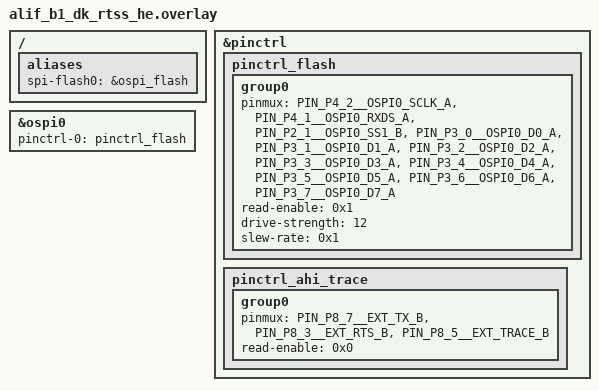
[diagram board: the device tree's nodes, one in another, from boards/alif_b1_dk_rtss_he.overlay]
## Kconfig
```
# Copyright (C) Alif Semiconductor - All Rights Reserved.
# Use, distribution and modification of this code is permitted under the
# terms stated in the Alif Semiconductor Software License Agreement
#
# You should have received a copy of the Alif Semiconductor Software
# License Agreement with this file. If not, please write to:
# contact@alifsemi.com, or visit: https://alifsemi.com/license

mainmenu "Alif OSPI flash sample"

config ALIF_OSPI_FLASH_BOOT_XIP_IMAGE
	bool "Boot image from OSPI XIP"
	depends on ALIF_OSPI_FLASH_XIP
	help
	  Boot or jump to an image stored in OSPI flash XIP address space.
	  This option is only for demonstration purposes.

source "Kconfig.zephyr"
```

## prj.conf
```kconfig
# Copyright (C) 2026 Alif Semiconductor.
# SPDX-License-Identifier: Apache-2.0

CONFIG_STDOUT_CONSOLE=y
CONFIG_FLASH=y
CONFIG_LOG=y
CONFIG_EVENTS=y
CONFIG_MAIN_STACK_SIZE=8192
CONFIG_FLASH_LOG_LEVEL_DBG=n
CONFIG_LOG_MODE_IMMEDIATE=y

#For Enable XiP
CONFIG_ALIF_OSPI_FLASH_XIP=n

#For Booting image in XiP mode from flash
CONFIG_ALIF_OSPI_FLASH_BOOT_XIP_IMAGE=n
```

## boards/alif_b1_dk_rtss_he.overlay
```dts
/* Copyright (C) 2024 Alif Semiconductor - All Rights Reserved.
 * Use, distribution and modification of this code is permitted under the
 * terms stated in the Alif Semiconductor Software License Agreement
 *
 * You should have received a copy of the Alif Semiconductor Software
 * License Agreement with this file. If not, please write to:
 * contact@alifsemi.com, or visit: https://alifsemi.com/license
 */

/{
	aliases {
		spi-flash0 = &ospi_flash;
	};
};

&pinctrl {
	//Flash connected with "P2_1_OSPI0_SS1_B" CS line
	pinctrl_flash:pinctrl_flash {
		group0 {
			pinmux = <PIN_P4_2__OSPI0_SCLK_A>,
				 <PIN_P4_1__OSPI0_RXDS_A>,
				 <PIN_P2_1__OSPI0_SS1_B>,
				 <PIN_P3_0__OSPI0_D0_A>,
				 <PIN_P3_1__OSPI0_D1_A>,
				 <PIN_P3_2__OSPI0_D2_A>,
				 <PIN_P3_3__OSPI0_D3_A>,
				 <PIN_P3_4__OSPI0_D4_A>,
				 <PIN_P3_5__OSPI0_D5_A>,
				 <PIN_P3_6__OSPI0_D6_A>,
				 <PIN_P3_7__OSPI0_D7_A>;
			read-enable = <0x1>;
			drive-strength = <12>;
			slew-rate = <0x1>;
		};
	};

	//Default AHI Trace pins affects OSPI-Flash pins.
	pinctrl_ahi_trace: pinctrl_ahi_trace {
		group0 {
			pinmux = <PIN_P8_7__EXT_TX_B>,
				 <PIN_P8_3__EXT_RTS_B>,
				 <PIN_P8_5__EXT_TRACE_B>;
			read-enable = < 0x0 >;
		};
	};
};

&ospi0 {
	pinctrl-0 = <&pinctrl_flash>;
	status = "okay";
};
```

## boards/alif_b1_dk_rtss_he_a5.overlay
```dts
/* Copyright (C) 2025 Alif Semiconductor - All Rights Reserved.
 * Use, distribution and modification of this code is permitted under the
 * terms stated in the Alif Semiconductor Software License Agreement
 *
 * You should have received a copy of the Alif Semiconductor Software
 * License Agreement with this file. If not, please write to:
 * contact@alifsemi.com, or visit: https://alifsemi.com/license
 */

/*
 * OSPI0 Test with Flash
 */
/{
	aliases {
		spi-flash0 = &ospi_flash;
	};
};

&ospi0 {
	pinctrl-0 = <&pinctrl_flash>;
	xip-base-address = <0xB0000000 0x20000000>;
	status = "okay";
};


&pinctrl {
	//A5-B1-DK Flash connected with "P2_1_OSPI0_SS1_B" CS line
	pinctrl_flash:pinctrl_flash {
		group0 {
			pinmux = <PIN_P4_2__OSPI0_SCLK_A>,
				 <PIN_P4_1__OSPI0_RXDS_A>,
				 <PIN_P2_1__OSPI0_SS1_B>,
				 <PIN_P3_0__OSPI0_D0_A>,
				 <PIN_P3_1__OSPI0_D1_A>,
				 <PIN_P3_2__OSPI0_D2_A>,
				 <PIN_P3_3__OSPI0_D3_A>,
				 <PIN_P3_4__OSPI0_D4_A>,
				 <PIN_P3_5__OSPI0_D5_A>,
				 <PIN_P3_6__OSPI0_D6_A>,
				 <PIN_P3_7__OSPI0_D7_A>;
			read_enable = <0x1>;
			drive_strength = <12>;
			slew_rate = <0x1>;
		};
	};

	//Default AHI Trace pins affects connected OSPI-Flash pins.
	pinctrl_ahi_trace: pinctrl_ahi_trace {
		group0 {
			pinmux = <PIN_P8_7__EXT_TX_B>,
				 <PIN_P8_3__EXT_RTS_B>,
				 <PIN_P8_5__EXT_TRACE_B>;
			read_enable = < 0x0 >;
		};
	};
};
```

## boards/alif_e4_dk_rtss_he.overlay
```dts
/* Copyright (C) 2025 Alif Semiconductor - All Rights Reserved.
 * Use, distribution and modification of this code is permitted under the
 * terms stated in the Alif Semiconductor Software License Agreement
 *
 * You should have received a copy of the Alif Semiconductor Software
 * License Agreement with this file. If not, please write to:
 * contact@alifsemi.com, or visit: https: //alifsemi.com/license
 *
 */

/*
 * For OSPI1 Test with Flash
 */

/ {
	aliases {
		spi-flash0 = &ospi_flash;
	};
};

&ospi1 {
	status = "okay";
	pinctrl-0 = <&pinctrl_flash>;
};
```

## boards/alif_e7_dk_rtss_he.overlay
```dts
/*
 * Copyright (c) 2024 Alif Semiconductor.
 * SPDX-License-Identifier: Apache-2.0
 */


/* For OSPI1 Test with Flash
 *
 */
/ {
	aliases {
		spi-flash0 = &ospi1;
	};
};
&ospi1 {
        pinctrl-0 = <&pinctrl_flash>;
	status = "okay";
};
```

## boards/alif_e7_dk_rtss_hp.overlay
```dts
/*
 * Copyright (c) 2024 Alif Semiconductor.
 * SPDX-License-Identifier: Apache-2.0
 */

/ {
	aliases {
		spi-flash0 = &ospi1;
	};
};
&ospi1 {
	status = "okay";
        pinctrl-0 = <&pinctrl_flash>;
};
```

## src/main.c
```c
/*
 * Copyright (c) 2024 Alif Semiconductor
 * SPDX-License-Identifier: Apache-2.0
 */

#include <stdio.h>
#include <string.h>
#include <zephyr/device.h>
#include <zephyr/devicetree.h>
#include <zephyr/drivers/flash.h>
#include <zephyr/kernel.h>

#define SPI_FLASH_TEST_REGION_OFFSET 0x0
#define SPI_FLASH_SECTOR_SIZE        4096
#define BUFF_SIZE                    1024

#ifdef CONFIG_ALIF_OSPI_FLASH_XIP
#define XIP_IMAGE_BASE DT_PROP_BY_IDX(DT_PARENT(DT_ALIAS(spi_flash0)), xip_base_address, 0)

FUNC_NORETURN static void boot_xip_image(void)
{
	uint32_t image_base = XIP_IMAGE_BASE;
	uint32_t initial_sp = *(uint32_t *)image_base;
	uint32_t reset_addr = *(uint32_t *)(image_base + sizeof(uint32_t));

	printf("\nBooting XiP image at 0x%08x\n", image_base);
	printf("Initial SP: 0x%08x, reset handler: 0x%08x\n\n\n", initial_sp, reset_addr);

	/* Clear the stack limit */
	__set_MSPLIM(0);

	/* Set the new vector table address */
	SCB->VTOR = image_base;

	/* Complete memory operations */
	__DSB();
	/* Refresh the instruction pipeline */
	__ISB();

	/* Set the new stack pointer and start the application */
	__asm volatile (
		"ldr sp, [%0, #0]\n\t"
		"ldr pc, [%0, #4]\n\t"
		:
		: "r" (image_base)
		: "memory"
	);

	CODE_UNREACHABLE;
}

#endif

const struct flash_parameters *flash_param;

void single_sector_test(const struct device *flash_dev)
{
	const uint8_t expected[] = {0x55, 0xaa, 0x66, 0x99};
	const size_t len = ARRAY_SIZE(expected);
	uint8_t buf[len];
	int rc;
	int i, e_count = 0;

	printf("\nTest 1: Flash erase\n");

	/* Full flash erase if SPI_FLASH_TEST_REGION_OFFSET = 0 and
	 * SPI_FLASH_SECTOR_SIZE = flash size
	 */
	rc = flash_erase(flash_dev, SPI_FLASH_TEST_REGION_OFFSET, SPI_FLASH_SECTOR_SIZE);
	if (rc != 0) {
		printf("Flash erase failed! %d\n", rc);
	} else {
		printf("Flash erase succeeded!\n");
	}

	printf("\nTest 1: Flash write\n");

	printf("Attempting to write %zu bytes\n", len);
	rc = flash_write(flash_dev, SPI_FLASH_TEST_REGION_OFFSET, expected, len);
	if (rc != 0) {
		printf("Flash write failed! %d\n", rc);
		return;
	}

	printf("\nTest 1: Flash read\n");

	memset(buf, 0, len);
	rc = flash_read(flash_dev, SPI_FLASH_TEST_REGION_OFFSET, buf, len);
	if (rc != 0) {
		printf("Flash read failed! %d\n", rc);
		return;
	}

	for (i = 0; i < len; i++) {
		if (buf[i] != expected[i]) {
			e_count++;
			printf("Not matched at [%d] _w[%4x] _r[%4x]\n", i, expected[i], buf[i]);
		}
	}

	if (e_count) {
		printf("Error:Data read NOT matches data written\n");
	} else {
		printf("Data read matches data written. Good!!\n");
	}
}

void erase_test(const struct device *dev, uint32_t len)
{
	int ret = 0, i = 0, count = 0;
	uint8_t r_buf[BUFF_SIZE] = {0};

	printf("\nTest 2: Flash Full Erase\n");

	ret = flash_erase(dev, SPI_FLASH_TEST_REGION_OFFSET, len);
	if (ret == 0) {
		printf("Successfully Erased whole Flash Memory\n");
	} else {
		printf("Error: Bulk Erase Failed [%d]\n", ret);
	}

	/* Read data Cleared Buffer */
	ret = flash_read(dev, SPI_FLASH_TEST_REGION_OFFSET, r_buf, BUFF_SIZE);
	if (ret != 0) {
		printf("Error: [RetVal :%d] Reading Erased value\n", ret);
		return;
	}

	/* Verify the read data */
	for (i = 0; i < BUFF_SIZE; i++) {
		if (r_buf[i] != flash_param->erase_value) {
			count++;
		}
	}

	printf("Total errors after reading erased chip = %d\n", count);
}

void multi_page_test(const struct device *flash_dev)
{
	int rc, i, e_count = 0;

	uint8_t w_buf[BUFF_SIZE] = {0};
	uint8_t r_buf[BUFF_SIZE] = {0};

	const size_t len = ARRAY_SIZE(w_buf);

	printf("\nTest 3: Flash erase\n");

	/* Full flash erase if SPI_FLASH_TEST_REGION_OFFSET = 0 and
	 * SPI_FLASH_SECTOR_SIZE = flash size
	 */
	rc = flash_erase(flash_dev, SPI_FLASH_TEST_REGION_OFFSET, SPI_FLASH_SECTOR_SIZE);
	if (rc != 0) {
		printf("Flash erase failed! %d\n", rc);
	} else {
		printf("Flash erase succeeded!\n");
	}

	for (i = 0; i < BUFF_SIZE; i++) {
		w_buf[i] = i % 256;
	}

	printf("\nTest 3: Flash write\n");

	printf("Attempting to write %zu bytes\n", len);
	rc = flash_write(flash_dev, SPI_FLASH_TEST_REGION_OFFSET, w_buf, len);
	if (rc != 0) {
		printf("Flash write failed! %d\n", rc);
		return;
	}

	printf("\nTest 3: Flash read\n");

	memset(r_buf, 0, len);
	rc = flash_read(flash_dev, SPI_FLASH_TEST_REGION_OFFSET, r_buf, len);
	if (rc != 0) {
		printf("Flash read failed! %d\n", rc);
		return;
	}

	for (i = 0; i < BUFF_SIZE; i++) {
		if (r_buf[i] != w_buf[i]) {
			e_count++;
			printf("Not matched at [%d] _w[%4x] _r[%4x]\n", i, w_buf[i], r_buf[i]);
		}
	}

	if (e_count) {
		printf("Error:Data read NOT matches data written\n");
		printf(" -- number of Unmatched data [%d]\n", e_count);
	} else {
		printf("Data read matches data written. Good!!\n");
	}
}

#define SPI_FLASH_SECTOR_4_OFFSET (4 * 1024 * 4)
#define SPI_FLASH_SECTOR_5_OFFSET (5 * 1024 * 4)

void multi_sector_test(const struct device *flash_dev)
{
	int rc, i, e_count = 0;

	uint8_t w_buf[BUFF_SIZE] = {0};
	uint8_t r_buf[BUFF_SIZE] = {0};

	const size_t len = ARRAY_SIZE(w_buf);

	for (i = 0; i < BUFF_SIZE; i++) {
		w_buf[i] =  i % 256;
	}

	printf("\nTest 4: write sector %d\n", SPI_FLASH_SECTOR_4_OFFSET);
	/* Write into Sector 4 */
	rc = flash_write(flash_dev, SPI_FLASH_SECTOR_4_OFFSET, w_buf, len);
	if (rc != 0) {
		printf("\nFlash write failed at Sec 4! %d\n", rc);
		return;
	}

	printf("\nTest 4: write sector %d\n", SPI_FLASH_SECTOR_5_OFFSET);
	/* Write into Sector 5 */
	rc = flash_write(flash_dev, SPI_FLASH_SECTOR_5_OFFSET, w_buf, len);
	if (rc != 0) {
		printf("\nFlash write failed at Sec 5! %d\n", rc);
		return;
	}

	/* Read from Sector 4 */
	printf("Sec4: Read and Verify written data\n");

	e_count = 0;
	memset(r_buf, 0, len);

	printf("\nTest 4: read sector %d\n", SPI_FLASH_SECTOR_4_OFFSET);

	rc = flash_read(flash_dev, SPI_FLASH_SECTOR_4_OFFSET, r_buf, len);
	if (rc != 0) {
		printf("Flash read failed at Sector 4! %d\n", rc);
		return;
	}

	for (i = 0; i < BUFF_SIZE; i++) {
		if (r_buf[i] != w_buf[i]) {
			e_count++;
			printf("Not matched at [%d] _w[%4x] _r[%4x]\n", i, w_buf[i], r_buf[i]);
		}
	}

	if (e_count) {
		printf("\nError:Data read NOT matches data written\n");
		printf(" -- number of Unmatched data [%d]\n", e_count);
	} else {
		printf("\nData read matches data written. Good!!\n");
	}

	/* Read from Sector 5 */
	printf("Sec5: Read and Verify written data\n");

	e_count = 0;
	memset(r_buf, 0, len);

	printf("\nTest 4: read sector %d\n", SPI_FLASH_SECTOR_5_OFFSET);

	rc = flash_read(flash_dev, SPI_FLASH_SECTOR_5_OFFSET, r_buf, len);
	if (rc != 0) {
		printf("Flash read failed at Sector 5! %d\n", rc);
		return;
	}

	for (i = 0; i < BUFF_SIZE; i++) {
		if (r_buf[i] != w_buf[i]) {
			e_count++;
			printf("Not matched at [%d] _w[%4x] _r[%4x]\n", i, w_buf[i], r_buf[i]);
		}
	}

	if (e_count) {
		printf("Error:Data read NOT matches data written\n");
		printf(" -- number of Unmatched data [%d]\n", e_count);
	} else {
		printf("Data read matches data written. Good!!\n");
	}

	/* Erase multiple Sector Sec 4+5 */
	printf("\nTest 4: Erase Sector 4 and 5\n");
	printf("Flash Erase from Sector %d Size to Erase %d\n", SPI_FLASH_SECTOR_4_OFFSET,
	       SPI_FLASH_SECTOR_SIZE * 2);

	rc = flash_erase(flash_dev, SPI_FLASH_SECTOR_4_OFFSET, SPI_FLASH_SECTOR_SIZE * 2);
	if (rc != 0) {
		printf("\nMulti-Sector erase failed! %d\n", rc);
	} else {
		printf("\nMulti-Sector erase succeeded!\n");
	}

	int count_1 = 0;

	memset(r_buf, 0, len);

	printf("\nTest 4: read sector %d\n", SPI_FLASH_SECTOR_4_OFFSET);
	/* Read Erased value and compare */
	rc = flash_read(flash_dev, SPI_FLASH_SECTOR_4_OFFSET, r_buf, BUFF_SIZE);
	if (rc != 0) {
		printf("Error: [RetVal :%d] Reading Erased value\n", rc);
		return;
	}

	/* Verify the read data */
	for (i = 0; i < BUFF_SIZE; i++) {
		if (r_buf[i] != flash_param->erase_value) {
			count_1++;
		}
	}

	printf("Total errors after reading erased Sector 4 = %d\n", count_1);

	int count_2 = 0;

	memset(r_buf, 0, len);
	printf("\nTest 4: read sector %d\n", SPI_FLASH_SECTOR_5_OFFSET);

	/* Read Erased value and compare */
	rc = flash_read(flash_dev, SPI_FLASH_SECTOR_5_OFFSET, r_buf, BUFF_SIZE);
	if (rc != 0) {
		printf("Error: [RetVal :%d] Reading Erased value\n", rc);
		return;
	}

	/* Verify the read data */
	for (i = 0; i < BUFF_SIZE; i++) {
		if (r_buf[i] != flash_param->erase_value) {
			count_2++;
		}
	}

	printf("Total errors after reading erased Sector 5 = %d\n", count_2);

	if (count_1 == 0 && count_2 == 0) {
		printf("\nMulti-Sector Erase Test Succeeded !\n");
	} else {
		printf("\nMulti-Sector Erase Failed\n");
	}
}

void xip_test(const struct device *flash_dev)
{
	uint8_t i;
	uint32_t xip_r[64] = {0}, fls_r[64] = {0}, cnt;
	uint32_t *ptr = (uint32_t *)DT_PROP_BY_IDX(DT_PARENT(DT_ALIAS(spi_flash0)),
						xip_base_address, 0);
	int32_t rc, e_count = 0;

	printf("\nTest 5: XiP Read\n");

	memcpy(xip_r, ptr, sizeof(xip_r));

	printf("Content Read from OSPI Flash in XiP Mode successfully\n\n");

	cnt = ARRAY_SIZE(xip_r);

	printf("Read from Flash cmd while XiP Mode turnned on\n\n");

	rc = flash_read(flash_dev, SPI_FLASH_TEST_REGION_OFFSET,
				fls_r, cnt * sizeof(uint32_t));
	if (rc != 0) {
		printf("Flash read failed! %d\n", rc);
		return;
	}

	for (i = 0; i < cnt; i++)
		if (fls_r[i] != xip_r[i]) {
			e_count++;
		}

	if (!e_count) {
		printf("XiP Read Test Succceeded !!\n\n");
	} else {
		printf("XiP Test Failed !"
			" contents are NOT Matching : Err Count [%d]!!!\n", e_count);
	}
}


int main(void)
{
	const struct device *flash_dev = DEVICE_DT_GET(DT_ALIAS(spi_flash0));

	if (!device_is_ready(flash_dev)) {
		printk("%s: device not ready.\n", flash_dev->name);
		return -1;
	}

	printf("\n%s OSPI flash testing\n", flash_dev->name);
	printf("========================================\n");

	flash_param = flash_get_parameters(flash_dev);

	printf("****Flash Configured Parameters******\n");
	printf("* Bus Speed : %lu Hz\n",
	       (unsigned long)DT_PROP(DT_PARENT(DT_ALIAS(spi_flash0)), bus_speed));
	printf("* Num Of Sectors : %d\n", flash_param->num_of_sector);
	printf("* Sector Size : %d\n", flash_param->sector_size);
	printf("* Page Size : %d\n", flash_param->page_size);
	printf("* Erase value : %d\n", flash_param->erase_value);
	printf("* Write Blk Size: %d\n", flash_param->write_block_size);
	printf("* Total Size in MB: %d\n",
	       (flash_param->num_of_sector * flash_param->sector_size) / (1024 * 1024));

#if defined(CONFIG_ALIF_OSPI_FLASH_XIP) && defined(CONFIG_ALIF_OSPI_FLASH_BOOT_XIP_IMAGE)
	boot_xip_image();
	CODE_UNREACHABLE;
#endif

	/*Current RW support only on 16 DFS */
	single_sector_test(flash_dev);

	/* Erase Full and verify the content */
	erase_test(flash_dev, flash_param->num_of_sector * flash_param->sector_size);

	/* Multipage test */
	multi_page_test(flash_dev);

	/* Multi-Secot R/W and Erase test*/
	multi_sector_test(flash_dev);

#ifdef CONFIG_ALIF_OSPI_FLASH_XIP
	xip_test(flash_dev);
#endif

	return 0;
}
```
